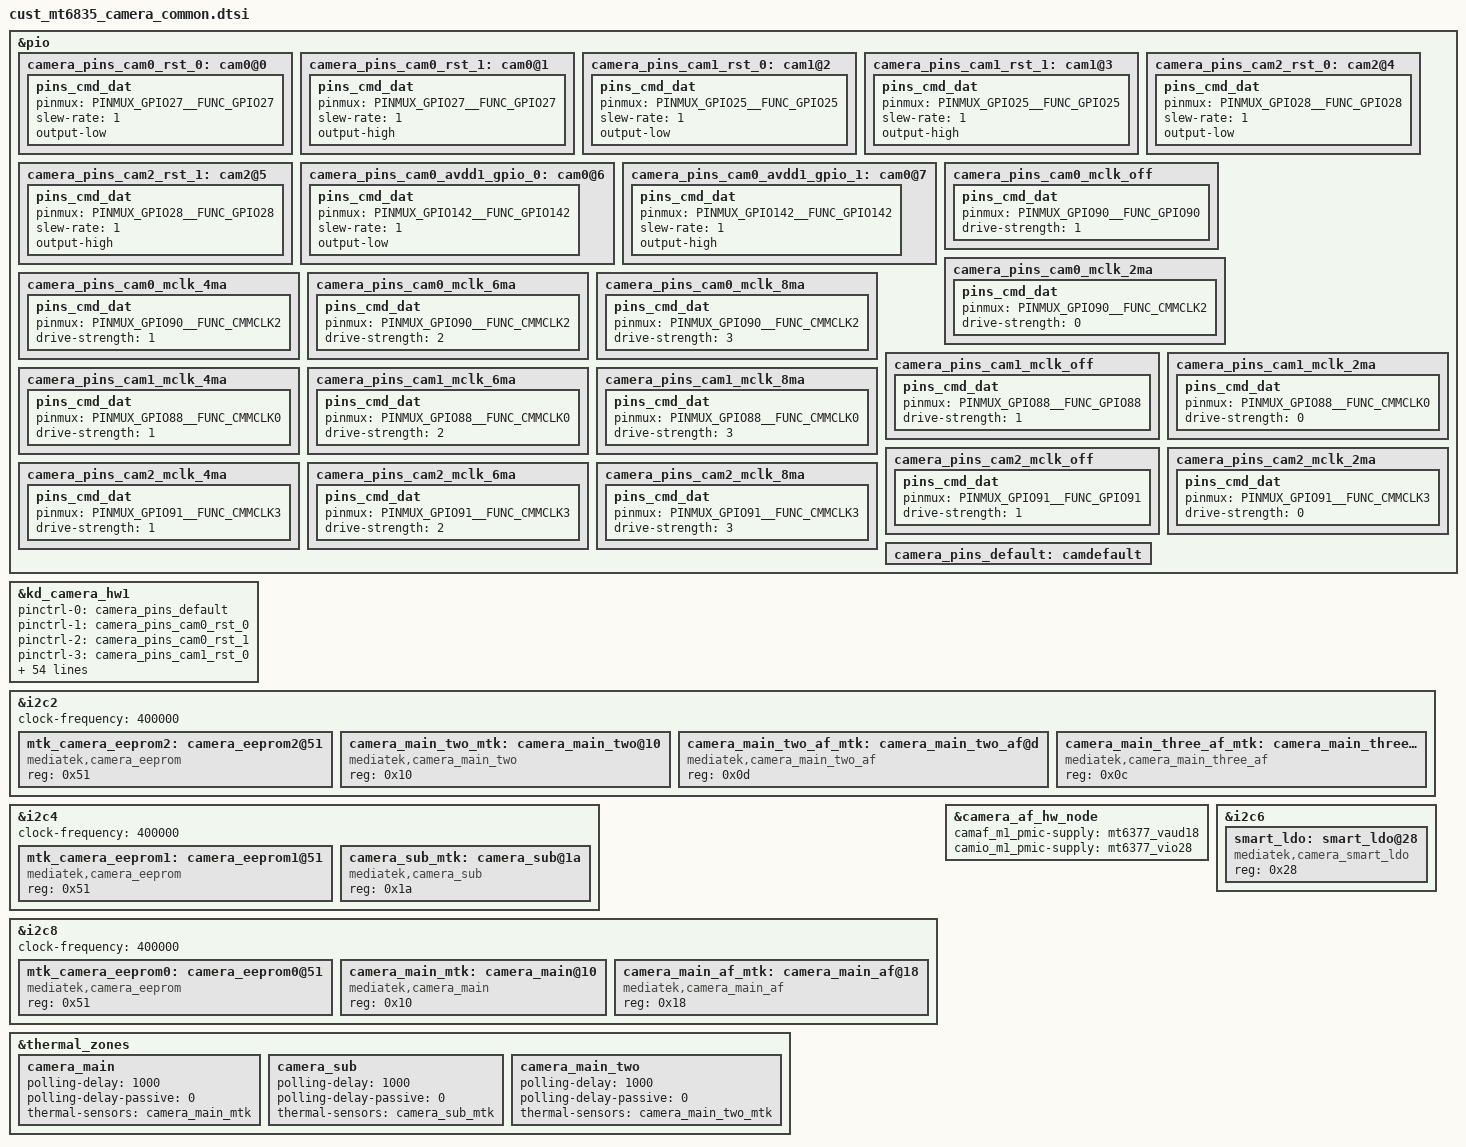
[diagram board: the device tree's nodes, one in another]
// SPDX-License-Identifier: GPL-2.0
/* Copyright (c) 2020 MediaTek Inc. */
/* CAMERA GPIO standardization */
&pio {
	camera_pins_cam0_rst_0: cam0@0 {
		pins_cmd_dat {
			pinmux = <PINMUX_GPIO27__FUNC_GPIO27>;
			slew-rate = <1>;
			output-low;
		};
	};
	camera_pins_cam0_rst_1: cam0@1 {
		pins_cmd_dat {
			pinmux = <PINMUX_GPIO27__FUNC_GPIO27>;
			slew-rate = <1>;
			output-high;
		};
	};
	camera_pins_cam1_rst_0: cam1@2 {
		pins_cmd_dat {
			pinmux = <PINMUX_GPIO25__FUNC_GPIO25>;
			slew-rate = <1>;
			output-low;
		};
	};
	camera_pins_cam1_rst_1: cam1@3 {
		pins_cmd_dat {
			pinmux = <PINMUX_GPIO25__FUNC_GPIO25>;
			slew-rate = <1>;
			output-high;
		};
	};
	camera_pins_cam2_rst_0: cam2@4 {
		pins_cmd_dat {
			pinmux = <PINMUX_GPIO28__FUNC_GPIO28>;
			slew-rate = <1>;
			output-low;
		};
	};
	camera_pins_cam2_rst_1: cam2@5 {
		pins_cmd_dat {
			pinmux = <PINMUX_GPIO28__FUNC_GPIO28>;
			slew-rate = <1>;
			output-high;
		};
	};
	camera_pins_cam0_avdd1_gpio_0: cam0@6 {
		pins_cmd_dat {
			pinmux = <PINMUX_GPIO142__FUNC_GPIO142>;
			slew-rate = <1>;
			output-low;
		};
	};
	camera_pins_cam0_avdd1_gpio_1: cam0@7 {
		pins_cmd_dat {
			pinmux = <PINMUX_GPIO142__FUNC_GPIO142>;
			slew-rate = <1>;
			output-high;
		};
	};
	camera_pins_cam0_mclk_off: camera_pins_cam0_mclk_off {
		pins_cmd_dat {
			pinmux = <PINMUX_GPIO90__FUNC_GPIO90>;
			drive-strength = <1>;
		};
	};
	camera_pins_cam0_mclk_2ma: camera_pins_cam0_mclk_2ma {
		pins_cmd_dat {
			pinmux = <PINMUX_GPIO90__FUNC_CMMCLK2>;
			drive-strength = <0>;
		};
	};
	camera_pins_cam0_mclk_4ma: camera_pins_cam0_mclk_4ma {
		pins_cmd_dat {
			pinmux = <PINMUX_GPIO90__FUNC_CMMCLK2>;
			drive-strength = <1>;
		};
	};
	camera_pins_cam0_mclk_6ma: camera_pins_cam0_mclk_6ma {
		pins_cmd_dat {
			pinmux = <PINMUX_GPIO90__FUNC_CMMCLK2>;
			drive-strength = <2>;
		};
	};
	camera_pins_cam0_mclk_8ma: camera_pins_cam0_mclk_8ma {
		pins_cmd_dat {
			pinmux = <PINMUX_GPIO90__FUNC_CMMCLK2>;
			drive-strength = <3>;
		};
	};
	camera_pins_cam1_mclk_off: camera_pins_cam1_mclk_off {
		pins_cmd_dat {
			pinmux = <PINMUX_GPIO88__FUNC_GPIO88>;
			drive-strength = <1>;
		};
	};
	camera_pins_cam1_mclk_2ma: camera_pins_cam1_mclk_2ma {
		pins_cmd_dat {
			pinmux = <PINMUX_GPIO88__FUNC_CMMCLK0>;
			drive-strength = <0>;
		};
	};
	camera_pins_cam1_mclk_4ma: camera_pins_cam1_mclk_4ma {
		pins_cmd_dat {
			pinmux = <PINMUX_GPIO88__FUNC_CMMCLK0>;
			drive-strength = <1>;
		};
	};
	camera_pins_cam1_mclk_6ma: camera_pins_cam1_mclk_6ma {
		pins_cmd_dat {
			pinmux = <PINMUX_GPIO88__FUNC_CMMCLK0>;
			drive-strength = <2>;
		};
	};
	camera_pins_cam1_mclk_8ma: camera_pins_cam1_mclk_8ma {
		pins_cmd_dat {
			pinmux = <PINMUX_GPIO88__FUNC_CMMCLK0>;
			drive-strength = <3>;
		};
	};
	camera_pins_cam2_mclk_off: camera_pins_cam2_mclk_off {
		pins_cmd_dat {
			pinmux = <PINMUX_GPIO91__FUNC_GPIO91>;
			drive-strength = <1>;
		};
	};
	camera_pins_cam2_mclk_2ma: camera_pins_cam2_mclk_2ma {
		pins_cmd_dat {
			pinmux = <PINMUX_GPIO91__FUNC_CMMCLK3>;
			drive-strength = <0>;
		};
	};
	camera_pins_cam2_mclk_4ma: camera_pins_cam2_mclk_4ma {
		pins_cmd_dat {
			pinmux = <PINMUX_GPIO91__FUNC_CMMCLK3>;
			drive-strength = <1>;
		};
	};
	camera_pins_cam2_mclk_6ma: camera_pins_cam2_mclk_6ma {
		pins_cmd_dat {
			pinmux = <PINMUX_GPIO91__FUNC_CMMCLK3>;
			drive-strength = <2>;
		};
	};
	camera_pins_cam2_mclk_8ma: camera_pins_cam2_mclk_8ma {
		pins_cmd_dat {
			pinmux = <PINMUX_GPIO91__FUNC_CMMCLK3>;
			drive-strength = <3>;
		};
	};
	camera_pins_default: camdefault {
	};
};
&kd_camera_hw1 {
	pinctrl-names = "default",
			"cam0_rst0", "cam0_rst1",
			"cam1_rst0", "cam1_rst1",
			"cam2_rst0", "cam2_rst1",
			"cam0_mclk_off",
			"cam0_mclk_2mA", "cam0_mclk_4mA",
			"cam0_mclk_6mA", "cam0_mclk_8mA",
			"cam1_mclk_off",
			"cam1_mclk_2mA", "cam1_mclk_4mA",
			"cam1_mclk_6mA", "cam1_mclk_8mA",
			"cam2_mclk_off",
			"cam2_mclk_2mA", "cam2_mclk_4mA",
			"cam2_mclk_6mA", "cam2_mclk_8mA",
			"cam0_avdd1_gpio_0",  "cam0_avdd1_gpio_1";
	pinctrl-0 = <&camera_pins_default>;
	pinctrl-1 = <&camera_pins_cam0_rst_0>;
	pinctrl-2 = <&camera_pins_cam0_rst_1>;
	pinctrl-3 = <&camera_pins_cam1_rst_0>;
	pinctrl-4 = <&camera_pins_cam1_rst_1>;
	pinctrl-5 = <&camera_pins_cam2_rst_0>;
	pinctrl-6 = <&camera_pins_cam2_rst_1>;
	pinctrl-7 = <&camera_pins_cam0_mclk_off>;
	pinctrl-8 = <&camera_pins_cam0_mclk_2ma>;
	pinctrl-9 = <&camera_pins_cam0_mclk_4ma>;
	pinctrl-10 = <&camera_pins_cam0_mclk_6ma>;
	pinctrl-11 = <&camera_pins_cam0_mclk_8ma>;
	pinctrl-12 = <&camera_pins_cam1_mclk_off>;
	pinctrl-13 = <&camera_pins_cam1_mclk_2ma>;
	pinctrl-14 = <&camera_pins_cam1_mclk_4ma>;
	pinctrl-15 = <&camera_pins_cam1_mclk_6ma>;
	pinctrl-16 = <&camera_pins_cam1_mclk_8ma>;
	pinctrl-17 = <&camera_pins_cam2_mclk_off>;
	pinctrl-18 = <&camera_pins_cam2_mclk_2ma>;
	pinctrl-19 = <&camera_pins_cam2_mclk_4ma>;
	pinctrl-20 = <&camera_pins_cam2_mclk_6ma>;
	pinctrl-21 = <&camera_pins_cam2_mclk_8ma>;
	pinctrl-22 = <&camera_pins_cam0_avdd1_gpio_0>;
	pinctrl-23 = <&camera_pins_cam0_avdd1_gpio_1>;

	/* main (wide)*/
	cam0_vcamio-supply = <&mt6377_vaud18>;
	cam0_vcamaf-supply = <&mt6377_vio28>;

	/* front*/
	cam1_vcamio-supply = <&mt6377_vaud18>;

	/* main2 (Ultra Wide)*/
	cam2_vcamio-supply = <&mt6377_vaud18>;

	cam0_pin_mclk = "mclk";
	cam0_pin_rst = "gpio";
	cam0_pin_vcama = "smartldo";
	cam0_pin_vcamio = "regulator";
	cam0_pin_vcamd = "smartldo";
	cam0_pin_vcama1 = "regulator";
	cam0_pin_vcama1_gpio = "gpio";
	cam0_pin_vcamaf = "regulator";
	cam1_pin_mclk = "mclk";
	cam1_pin_rst = "gpio";
	cam1_pin_vcama = "smartldo";
	cam1_pin_vcamio = "regulator";
	cam1_pin_vcamd = "smartldo";
	cam1_pin_vcama1 = "regulator";
	cam2_pin_mclk = "mclk";
	cam2_pin_rst = "gpio";
	cam2_pin_vcama = "smartldo";
	cam2_pin_vcamio = "regulator";
	cam2_pin_vcamd = "smartldo";
	cam2_pin_vcama1 = "regulator";
	cam2_pin_vcamaf = "regulator";
	cam3_pin_mclk = "mclk";
	cam3_pin_rst = "gpio";
	cam3_pin_vcama = "smartldo";
	cam3_pin_vcamd = "smartldo";
	cam3_pin_vcamio = "regulator";
	cam0_enable_sensor = "ov50d40_truly_main_i_mipi_raw s5kjns_sunny_main_ii_mipi_raw s5kjns_sunny_main_iii_mipi_raw";
	cam1_enable_sensor = "sc520_truly_front_i_mipi_raw gc05a2_qtech_front_ii_mipi_raw";
	status = "okay";
};
/* CAMERA GPIO end */

/* CAMERA EEPROM */
&i2c2 {
	status = "okay";
	clock-frequency = <400000>;
	#address-cells = <1>;
	#size-cells = <0>;

	mtk_camera_eeprom2:camera_eeprom2@51 {
		compatible = "mediatek,camera_eeprom";
		reg = <0x51>;
		status = "okay";
	};
	camera_main_two_mtk:camera_main_two@10 {
		compatible = "mediatek,camera_main_two";
		#thermal-sensor-cells = <0>;
		reg = <0x10>;
		status = "okay";
	};
};
&i2c4 {
	status = "okay";
	clock-frequency = <400000>;
	#address-cells = <1>;
	#size-cells = <0>;

	mtk_camera_eeprom1:camera_eeprom1@51 {
		compatible = "mediatek,camera_eeprom";
		reg = <0x51>;
		status = "okay";
	};
	camera_sub_mtk:camera_sub@1a {
		compatible = "mediatek,camera_sub";
		#thermal-sensor-cells = <0>;
		reg = <0x1a>;
		status = "okay";
	};
};
&i2c8 {
	status = "okay";
	clock-frequency = <400000>;
	#address-cells = <1>;
	#size-cells = <0>;

	mtk_camera_eeprom0:camera_eeprom0@51 {
		compatible = "mediatek,camera_eeprom";
		reg = <0x51>;
		status = "okay";
	};
	camera_main_mtk:camera_main@10 {
		compatible = "mediatek,camera_main";
		#thermal-sensor-cells = <0>;
		reg = <0x10>;
		status = "okay";
	};
};
/* CAMERA EEPROM end */

/* CAMERA AF */
&i2c8 {
	camera_main_af_mtk:camera_main_af@18 {
		compatible = "mediatek,camera_main_af";
		reg = <0x18>;
		status = "okay";
	};
};

&i2c2 {
	camera_main_two_af_mtk:camera_main_two_af@d {
		compatible = "mediatek,camera_main_two_af";
		reg = <0x0d>;
		status = "okay";
	};

	camera_main_three_af_mtk:camera_main_three_af@c {
		compatible = "mediatek,camera_main_three_af";
		reg = <0x0c>;
		status = "okay";
	};
};

&camera_af_hw_node {
	camaf_m1_pmic-supply = <&mt6377_vaud18>;
	camio_m1_pmic-supply = <&mt6377_vio28>;
	status = "okay";
};
/* CAMERA AF end */

/* CAMERA TZ config */
&thermal_zones {
	camera_main: camera_main {
		polling-delay = <1000>; /* milliseconds */
		polling-delay-passive = <0>; /* milliseconds */
		thermal-sensors = <&camera_main_mtk>;
	};
	camera_sub: camera_sub {
		polling-delay = <1000>; /* milliseconds */
		polling-delay-passive = <0>; /* milliseconds */
		thermal-sensors = <&camera_sub_mtk>;
	};
	camera_main_two: camera_main_two {
		polling-delay = <1000>; /* milliseconds */
		polling-delay-passive = <0>; /* milliseconds */
		thermal-sensors = <&camera_main_two_mtk>;
	};
};
/* CAMERA TZ config end */

/* CAMERA SMART LDO */
&i2c6 {
    smart_ldo:smart_ldo@28 {
        compatible = "mediatek,camera_smart_ldo";
		reg = <0x28>;
		status = "okay";
	};
};
/* CAMERA SMART LDO  end */
